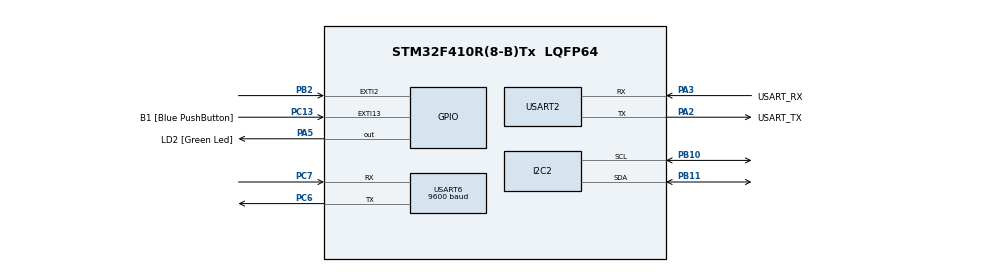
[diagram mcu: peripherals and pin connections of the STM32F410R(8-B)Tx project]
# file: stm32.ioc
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I2C2.I2C_Mode=I2C_Standard
Mcu.Family=STM32F4
Mcu.Name=STM32F410R(8-B)Tx
Mcu.Package=LQFP64
NVIC.PriorityGroup=NVIC_PRIORITYGROUP_0
PA13.GPIO_Label=TMS
PA13.Mode=Serial_Wire
PA13.Signal=SYS_JTMS-SWDIO
PA14.GPIO_Label=TCK
PA14.Mode=Serial_Wire
PA14.Signal=SYS_JTCK-SWCLK
PA2.GPIO_Label=USART_TX
PA2.Mode=Asynchronous
PA2.Signal=USART2_TX
PA3.GPIO_Label=USART_RX
PA3.Mode=Asynchronous
PA3.Signal=USART2_RX
PA5.GPIO_Label=LD2 [Green Led]
PA5.Signal=GPIO_Output
PB10.Mode=I2C
PB10.Signal=I2C2_SCL
PB11.Mode=I2C
PB11.Signal=I2C2_SDA
PB2.GPIO_PuPd=GPIO_NOPULL
PB2.Signal=GPXTI2
PB3.GPIO_Label=SWO
PB3.Signal=SYS_JTDO-SWO
PC13-ANTI_TAMP.GPIO_Label=B1 [Blue PushButton]
PC13-ANTI_TAMP.GPIO_ModeDefaultEXTI=GPIO_MODE_IT_FALLING
PC13-ANTI_TAMP.Signal=GPXTI13
PC14-OSC32_IN.Mode=LSE-External-Oscillator
PC14-OSC32_IN.Signal=RCC_OSC32_IN
PC15-OSC32_OUT.Mode=LSE-External-Oscillator
PC15-OSC32_OUT.Signal=RCC_OSC32_OUT
PC6.Mode=Asynchronous
PC6.Signal=USART6_TX
PC7.Mode=Asynchronous
PC7.Signal=USART6_RX
PH0\ -\ OSC_IN.Mode=HSE-External-Clock-Source
PH0\ -\ OSC_IN.Signal=RCC_OSC_IN
PH1\ -\ OSC_OUT.Mode=HSE-External-Clock-Source
PH1\ -\ OSC_OUT.Signal=RCC_OSC_OUT
ProjectManager.HeapSize=0x200
ProjectManager.StackSize=0x400
ProjectManager.TargetToolchain=CMake
RCC.48MHZClocksFreq_Value=84000000
RCC.AHBFreq_Value=84000000
RCC.APB1CLKDivider=RCC_HCLK_DIV2
RCC.APB1Freq_Value=42000000
RCC.APB1TimFreq_Value=84000000
RCC.APB2Freq_Value=84000000
RCC.APB2TimFreq_Value=84000000
RCC.CortexFreq_Value=84000000
RCC.FLatency-AdvancedSettings=FLASH_LATENCY_2
RCC.HCLKFreq_Value=84000000
RCC.HSE_VALUE=8000000
RCC.HSI_VALUE=16000000
RCC.PLLN=336
RCC.PLLP=RCC_PLLP_DIV4
RCC.SYSCLKFreq_VALUE=84000000
RCC.SYSCLKSource=RCC_SYSCLKSOURCE_PLLCLK
RCC.VCOOutputFreq_Value=336000000
USART2.VirtualMode=VM_ASYNC
USART6.BaudRate=9600
USART6.VirtualMode=VM_ASYNC
board=NUCLEO-F410RB

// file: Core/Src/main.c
/* USER CODE BEGIN Header */
/**
  ******************************************************************************
  * @file           : main.c
  * @brief          : Main program body
  ******************************************************************************
  * @attention
  *
  * Copyright (c) 2025 STMicroelectronics.
  * All rights reserved.
  *
  * This software is licensed under terms that can be found in the LICENSE file
  * in the root directory of this software component.
  * If no LICENSE file comes with this software, it is provided AS-IS.
  *
  ******************************************************************************
  */
/* USER CODE END Header */
#include "main.h"

void SystemClock_Config(void);
static void MX_GPIO_Init(void);
static void MX_USART2_UART_Init(void);
static void MX_USART6_UART_Init(void);
static void MX_I2C2_Init(void);
/* USER CODE BEGIN PFP */
void app_main(void);

/* USER CODE END PFP */

int main(void)
{

  /* MCU Configuration--------------------------------------------------------*/

  /* Reset of all peripherals, Initializes the Flash interface and the Systick. */
  LL_APB2_GRP1_EnableClock(LL_APB2_GRP1_PERIPH_SYSCFG);
  LL_APB1_GRP1_EnableClock(LL_APB1_GRP1_PERIPH_PWR);

  /* System interrupt init*/
  NVIC_SetPriorityGrouping(NVIC_PRIORITYGROUP_0);

  /* Configure the system clock */
  SystemClock_Config();

  /* Initialize all configured peripherals */
  MX_GPIO_Init();
  MX_USART2_UART_Init();
  MX_USART6_UART_Init();
  MX_I2C2_Init();

  /* Infinite loop */
  while (1)
  {

  }
}

void SystemClock_Config(void)
{
  LL_FLASH_SetLatency(LL_FLASH_LATENCY_2);
  while(LL_FLASH_GetLatency()!= LL_FLASH_LATENCY_2)
  {
  }
  LL_PWR_SetRegulVoltageScaling(LL_PWR_REGU_VOLTAGE_SCALE1);
  LL_RCC_HSI_SetCalibTrimming(16);
  LL_RCC_HSI_Enable();

   /* Wait till HSI is ready */
  while(LL_RCC_HSI_IsReady() != 1)
  {

  }
  LL_RCC_PLL_ConfigDomain_SYS(LL_RCC_PLLSOURCE_HSI, LL_RCC_PLLM_DIV_16, 336, LL_RCC_PLLP_DIV_4);
  LL_RCC_PLL_Enable();

   /* Wait till PLL is ready */
  while(LL_RCC_PLL_IsReady() != 1)
  {

  }
  while (LL_PWR_IsActiveFlag_VOS() == 0)
  {
  }
  LL_RCC_SetAHBPrescaler(LL_RCC_SYSCLK_DIV_1);
  LL_RCC_SetAPB1Prescaler(LL_RCC_APB1_DIV_2);
  LL_RCC_SetAPB2Prescaler(LL_RCC_APB2_DIV_1);
  LL_RCC_SetSysClkSource(LL_RCC_SYS_CLKSOURCE_PLL);

   /* Wait till System clock is ready */
  while(LL_RCC_GetSysClkSource() != LL_RCC_SYS_CLKSOURCE_STATUS_PLL)
  {

  }
  LL_Init1msTick(84000000);
  LL_SetSystemCoreClock(84000000);
  LL_RCC_SetTIMPrescaler(LL_RCC_TIM_PRESCALER_TWICE);
}

static void MX_I2C2_Init(void)
{

  LL_I2C_InitTypeDef I2C_InitStruct = {0};

  LL_GPIO_InitTypeDef GPIO_InitStruct = {0};

  LL_AHB1_GRP1_EnableClock(LL_AHB1_GRP1_PERIPH_GPIOB);
  /**I2C2 GPIO Configuration
  PB10   ------> I2C2_SCL
  PB11   ------> I2C2_SDA
  */
  GPIO_InitStruct.Pin = LL_GPIO_PIN_10|LL_GPIO_PIN_11;
  GPIO_InitStruct.Mode = LL_GPIO_MODE_ALTERNATE;
  GPIO_InitStruct.Speed = LL_GPIO_SPEED_FREQ_VERY_HIGH;
  GPIO_InitStruct.OutputType = LL_GPIO_OUTPUT_OPENDRAIN;
  GPIO_InitStruct.Pull = LL_GPIO_PULL_NO;
  GPIO_InitStruct.Alternate = LL_GPIO_AF_4;
  LL_GPIO_Init(GPIOB, &GPIO_InitStruct);

  /* Peripheral clock enable */
  LL_APB1_GRP1_EnableClock(LL_APB1_GRP1_PERIPH_I2C2);

  /** I2C Initialization
  */
  LL_I2C_DisableOwnAddress2(I2C2);
  LL_I2C_DisableGeneralCall(I2C2);
  LL_I2C_EnableClockStretching(I2C2);
  I2C_InitStruct.PeripheralMode = LL_I2C_MODE_I2C;
  I2C_InitStruct.ClockSpeed = 100000;
  I2C_InitStruct.DutyCycle = LL_I2C_DUTYCYCLE_2;
  I2C_InitStruct.OwnAddress1 = 0;
  I2C_InitStruct.TypeAcknowledge = LL_I2C_ACK;
  I2C_InitStruct.OwnAddrSize = LL_I2C_OWNADDRESS1_7BIT;
  LL_I2C_Init(I2C2, &I2C_InitStruct);
  LL_I2C_SetOwnAddress2(I2C2, 0);

}

static void MX_USART2_UART_Init(void)
{

  LL_USART_InitTypeDef USART_InitStruct = {0};

  LL_GPIO_InitTypeDef GPIO_InitStruct = {0};

  /* Peripheral clock enable */
  LL_APB1_GRP1_EnableClock(LL_APB1_GRP1_PERIPH_USART2);

  LL_AHB1_GRP1_EnableClock(LL_AHB1_GRP1_PERIPH_GPIOA);
  /**USART2 GPIO Configuration
  PA2   ------> USART2_TX
  PA3   ------> USART2_RX
  */
  GPIO_InitStruct.Pin = USART_TX_Pin|USART_RX_Pin;
  GPIO_InitStruct.Mode = LL_GPIO_MODE_ALTERNATE;
  GPIO_InitStruct.Speed = LL_GPIO_SPEED_FREQ_VERY_HIGH;
  GPIO_InitStruct.OutputType = LL_GPIO_OUTPUT_PUSHPULL;
  GPIO_InitStruct.Pull = LL_GPIO_PULL_NO;
  GPIO_InitStruct.Alternate = LL_GPIO_AF_7;
  LL_GPIO_Init(GPIOA, &GPIO_InitStruct);

  USART_InitStruct.BaudRate = 115200;
  USART_InitStruct.DataWidth = LL_USART_DATAWIDTH_8B;
  USART_InitStruct.StopBits = LL_USART_STOPBITS_1;
  USART_InitStruct.Parity = LL_USART_PARITY_NONE;
  USART_InitStruct.TransferDirection = LL_USART_DIRECTION_TX_RX;
  USART_InitStruct.HardwareFlowControl = LL_USART_HWCONTROL_NONE;
  USART_InitStruct.OverSampling = LL_USART_OVERSAMPLING_16;
  LL_USART_Init(USART2, &USART_InitStruct);
  LL_USART_ConfigAsyncMode(USART2);
  LL_USART_Enable(USART2);

}

static void MX_USART6_UART_Init(void)
{

  LL_USART_InitTypeDef USART_InitStruct = {0};

  LL_GPIO_InitTypeDef GPIO_InitStruct = {0};

  /* Peripheral clock enable */
  LL_APB2_GRP1_EnableClock(LL_APB2_GRP1_PERIPH_USART6);

  LL_AHB1_GRP1_EnableClock(LL_AHB1_GRP1_PERIPH_GPIOC);
  /**USART6 GPIO Configuration
  PC6   ------> USART6_TX
  PC7   ------> USART6_RX
  */
  GPIO_InitStruct.Pin = LL_GPIO_PIN_6|LL_GPIO_PIN_7;
  GPIO_InitStruct.Mode = LL_GPIO_MODE_ALTERNATE;
  GPIO_InitStruct.Speed = LL_GPIO_SPEED_FREQ_VERY_HIGH;
  GPIO_InitStruct.OutputType = LL_GPIO_OUTPUT_PUSHPULL;
  GPIO_InitStruct.Pull = LL_GPIO_PULL_NO;
  GPIO_InitStruct.Alternate = LL_GPIO_AF_8;
  LL_GPIO_Init(GPIOC, &GPIO_InitStruct);

  USART_InitStruct.BaudRate = 9600;
  USART_InitStruct.DataWidth = LL_USART_DATAWIDTH_8B;
  USART_InitStruct.StopBits = LL_USART_STOPBITS_1;
  USART_InitStruct.Parity = LL_USART_PARITY_NONE;
  USART_InitStruct.TransferDirection = LL_USART_DIRECTION_TX_RX;
  USART_InitStruct.HardwareFlowControl = LL_USART_HWCONTROL_NONE;
  USART_InitStruct.OverSampling = LL_USART_OVERSAMPLING_16;
  LL_USART_Init(USART6, &USART_InitStruct);
  LL_USART_ConfigAsyncMode(USART6);
  LL_USART_Enable(USART6);

}

static void MX_GPIO_Init(void)
{
  LL_EXTI_InitTypeDef EXTI_InitStruct = {0};
  LL_GPIO_InitTypeDef GPIO_InitStruct = {0};

  /* GPIO Ports Clock Enable */
  LL_AHB1_GRP1_EnableClock(LL_AHB1_GRP1_PERIPH_GPIOC);
  LL_AHB1_GRP1_EnableClock(LL_AHB1_GRP1_PERIPH_GPIOH);
  LL_AHB1_GRP1_EnableClock(LL_AHB1_GRP1_PERIPH_GPIOA);
  LL_AHB1_GRP1_EnableClock(LL_AHB1_GRP1_PERIPH_GPIOB);

  /**/
  LL_GPIO_ResetOutputPin(LD2_GPIO_Port, LD2_Pin);

  /**/
  LL_SYSCFG_SetEXTISource(LL_SYSCFG_EXTI_PORTC, LL_SYSCFG_EXTI_LINE13);

  /**/
  LL_SYSCFG_SetEXTISource(LL_SYSCFG_EXTI_PORTB, LL_SYSCFG_EXTI_LINE2);

  /**/
  EXTI_InitStruct.Line_0_31 = LL_EXTI_LINE_13;
  EXTI_InitStruct.LineCommand = ENABLE;
  EXTI_InitStruct.Mode = LL_EXTI_MODE_IT;
  EXTI_InitStruct.Trigger = LL_EXTI_TRIGGER_FALLING;
  LL_EXTI_Init(&EXTI_InitStruct);

  /**/
  EXTI_InitStruct.Line_0_31 = LL_EXTI_LINE_2;
  EXTI_InitStruct.LineCommand = ENABLE;
  EXTI_InitStruct.Mode = LL_EXTI_MODE_IT;
  EXTI_InitStruct.Trigger = LL_EXTI_TRIGGER_RISING;
  LL_EXTI_Init(&EXTI_InitStruct);

  /**/
  LL_GPIO_SetPinPull(B1_GPIO_Port, B1_Pin, LL_GPIO_PULL_NO);

  /**/
  LL_GPIO_SetPinPull(GPIOB, LL_GPIO_PIN_2, LL_GPIO_PULL_NO);

  /**/
  LL_GPIO_SetPinMode(B1_GPIO_Port, B1_Pin, LL_GPIO_MODE_INPUT);

  /**/
  LL_GPIO_SetPinMode(GPIOB, LL_GPIO_PIN_2, LL_GPIO_MODE_INPUT);

  /**/
  GPIO_InitStruct.Pin = LD2_Pin;
  GPIO_InitStruct.Mode = LL_GPIO_MODE_OUTPUT;
  GPIO_InitStruct.Speed = LL_GPIO_SPEED_FREQ_LOW;
  GPIO_InitStruct.OutputType = LL_GPIO_OUTPUT_PUSHPULL;
  GPIO_InitStruct.Pull = LL_GPIO_PULL_NO;
  LL_GPIO_Init(LD2_GPIO_Port, &GPIO_InitStruct);

}

void Error_Handler(void)
{
  __disable_irq();
  while (1)
  {
  }
}
